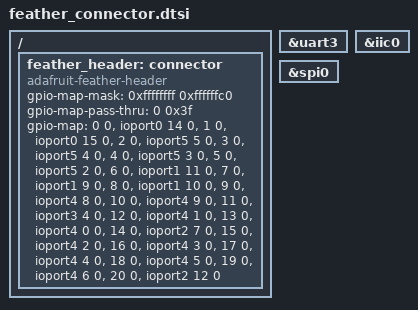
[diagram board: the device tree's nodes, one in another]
/*
 * Copyright (c) 2025 George White
 * SPDX-License-Identifier: Apache-2.0
 */

/ {
	feather_header: connector {
		compatible = "adafruit-feather-header";
		#gpio-cells = <2>;
		gpio-map-mask = <0xffffffff 0xffffffc0>;
		gpio-map-pass-thru = <0 0x3f>;
		gpio-map = <0 0 &ioport0 14 0>,		/* A0 */
			   <1 0 &ioport0 15 0>,		/* A1 */
			   <2 0 &ioport5 5 0>,		/* A2 */
			   <3 0 &ioport5 4 0>,		/* A3 */
			   <4 0 &ioport5 3 0>,		/* A4 */
			   <5 0 &ioport5 2 0>,		/* A5 */
			   <6 0 &ioport1 11 0>,		/* SCK */
			   <7 0 &ioport1 9 0>,		/* PICO */
			   <8 0 &ioport1 10 0>,		/* POCI */
			   <9 0 &ioport4 8 0>,		/* RX */
			   <10 0 &ioport4 9 0>,		/* TX */
			   <11 0 &ioport3 4 0>,		/* FREE */
			   <12 0 &ioport4 1 0>,		/* SDA */
			   <13 0 &ioport4 0 0>,		/* SCL */
			   <14 0 &ioport2 7 0>,		/* G6 */
			   <15 0 &ioport4 2 0>,		/* G5 */
			   <16 0 &ioport4 3 0>,		/* G4 */
			   <17 0 &ioport4 4 0>,		/* G3 */
			   <18 0 &ioport4 5 0>,		/* G2 */
			   <19 0 &ioport4 6 0>,		/* G1 */
			   <20 0 &ioport2 12 0>;	/* G0 */
	};
};

feather_serial: &uart3 {};

feather_i2c: &iic0 {};

feather_spi: &spi0 {};
